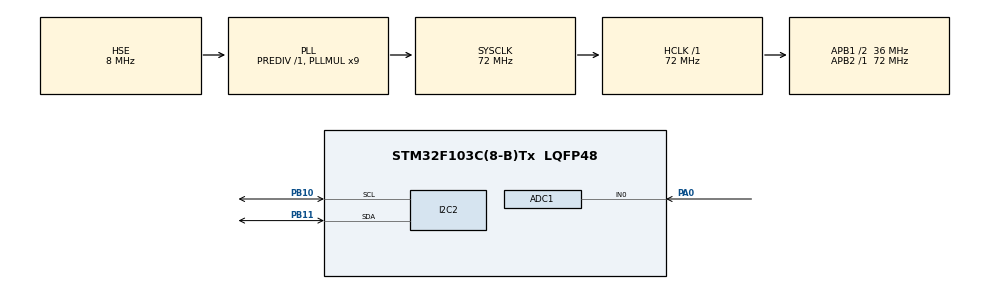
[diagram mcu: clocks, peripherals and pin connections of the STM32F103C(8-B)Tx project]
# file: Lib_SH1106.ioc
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Mcu.Family=STM32F1
RCC.PLLSourceVirtual=RCC_PLLSOURCE_HSE
PC15-OSC32_OUT.Mode=LSE-External-Oscillator
PD1-OSC_OUT.Mode=HSE-External-Oscillator
PB10.Mode=I2C
ADC1.ContinuousConvMode=ENABLE
PD0-OSC_IN.Signal=RCC_OSC_IN
RCC.APB1CLKDivider=RCC_HCLK_DIV2
PC14-OSC32_IN.Signal=RCC_OSC32_IN
PB11.Signal=I2C2_SDA
RCC.SYSCLKSource=RCC_SYSCLKSOURCE_PLLCLK
ProjectManager.StackSize=0x400
PA0-WKUP.Signal=ADCx_IN0
PD1-OSC_OUT.Signal=RCC_OSC_OUT
RCC.ADCPresc=RCC_ADCPCLK2_DIV6
PA13.Signal=SYS_JTMS-SWDIO
PB11.Mode=I2C
ProjectManager.TargetToolchain=STM32CubeIDE
RCC.HCLKFreq_Value=72000000
RCC.APB2TimFreq_Value=72000000
ADC1.Channel-1\#ChannelRegularConversion=ADC_CHANNEL_0
RCC.USBFreq_Value=72000000
PC15-OSC32_OUT.Signal=RCC_OSC32_OUT
RCC.AHBFreq_Value=72000000
PD0-OSC_IN.Mode=HSE-External-Oscillator
PB10.Signal=I2C2_SCL
board=custom
RCC.PLLMUL=RCC_PLL_MUL9
RCC.APB2Freq_Value=72000000
PC14-OSC32_IN.Mode=LSE-External-Oscillator
PA14.Mode=Serial_Wire
SH.ADCx_IN0.0=ADC1_IN0,IN0
ADC1.NbrOfConversion=1
PA13.Mode=Serial_Wire
Mcu.Name=STM32F103C(8-B)Tx
ADC1.SamplingTime-1\#ChannelRegularConversion=ADC_SAMPLETIME_1CYCLE_5
RCC.SYSCLKFreq_VALUE=72000000
Mcu.Package=LQFP48
ADC1.master=1
ADC1.Rank-1\#ChannelRegularConversion=1
PA14.Signal=SYS_JTCK-SWCLK
ProjectManager.HeapSize=0x200
NVIC.PriorityGroup=NVIC_PRIORITYGROUP_4
ADC1.NbrOfConversionFlag=1
RCC.APB1TimFreq_Value=72000000
RCC.APB1Freq_Value=36000000
I2C2.I2C_Mode=I2C_Fast

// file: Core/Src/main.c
/* USER CODE BEGIN Header */
/**
  ******************************************************************************
  * @file           : main.c
  * @brief          : Main program body
  ******************************************************************************
  * @attention
  *
  * <h2><center>&copy; Copyright (c) 2021 STMicroelectronics.
  * All rights reserved.</center></h2>
  *
  * This software component is licensed by ST under BSD 3-Clause license,
  * the "License"; You may not use this file except in compliance with the
  * License. You may obtain a copy of the License at:
  *                        opensource.org/licenses/BSD-3-Clause
  *
  ******************************************************************************
  */
/* USER CODE END Header */
#include "main.h"
#include "adc.h"
#include "i2c.h"
#include "gpio.h"

/* USER CODE BEGIN Includes */
#include <stdlib.h>
#include <usr/J3_SH1106.h>
#include <usr/font.h>

/* USER CODE END Includes */

/* USER CODE BEGIN PV */
//------------------------------------------------------------------------------
// File generated by LCD Assistant
// http://en.radzio.dxp.pl/bitmap_converter/
//------------------------------------------------------------------------------

const uint8_t pong [] = {
	0x00, 0x00, 0x00, 0x00, 0x00, 0x00, 0x00, 0x00, 0x00, 0x00, 0x00, 0x00, 0x00, 0x00, 0x00, 0x00,
	0x3F, 0xFF, 0xF0, 0x00, 0x1F, 0xFF, 0x80, 0x07, 0xFC, 0x07, 0xFE, 0x00, 0x1F, 0xFF, 0xF8, 0x00,
	0x7F, 0xFF, 0xF0, 0x00, 0x1F, 0xFF, 0x80, 0x0F, 0xFC, 0x07, 0xFF, 0x00, 0x3F, 0xFF, 0xF8, 0x00,
	0x40, 0x00, 0x10, 0x00, 0x10, 0x00, 0x00, 0x08, 0x00, 0x04, 0x01, 0x00, 0x20, 0x00, 0x08, 0x00,
	0x4F, 0xFF, 0xD0, 0x00, 0x17, 0xFE, 0x00, 0x09, 0xF0, 0x04, 0xF9, 0x00, 0x2F, 0xFF, 0xE8, 0x00,
	0x4F, 0xFF, 0xD0, 0x00, 0x17, 0xFE, 0x00, 0x09, 0xF0, 0x04, 0xF9, 0x00, 0x2F, 0xFF, 0xE8, 0x00,
	0x4F, 0xC0, 0xCF, 0x01, 0xF6, 0x06, 0x7C, 0x09, 0xF3, 0xE4, 0xF9, 0x03, 0xEC, 0x00, 0x08, 0x00,
	0x4F, 0xDE, 0xC1, 0x01, 0x06, 0xF6, 0x04, 0x09, 0xF0, 0x24, 0xF9, 0x02, 0x0C, 0xFF, 0xF8, 0x00,
	0x4F, 0xDE, 0xFD, 0x01, 0x7E, 0xF3, 0xE4, 0x09, 0xFF, 0xA4, 0xF9, 0x02, 0xFC, 0x80, 0x00, 0x00,
	0x4F, 0xDE, 0xFD, 0x01, 0x7E, 0xF3, 0xE4, 0x09, 0xFF, 0xA4, 0xF9, 0x02, 0xFC, 0x80, 0x00, 0x00,
	0x4F, 0xDE, 0xE1, 0x01, 0x7E, 0xF3, 0xE4, 0x09, 0xFF, 0xBC, 0xF9, 0x02, 0xFC, 0x9F, 0xF8, 0x00,
	0x4F, 0xC0, 0xDF, 0x01, 0x7E, 0xF3, 0xE4, 0x09, 0xFF, 0x81, 0xF9, 0x02, 0xFC, 0xB0, 0x08, 0x00,
	0x4F, 0xF3, 0xD0, 0x01, 0x7E, 0xF3, 0xE4, 0x09, 0xFF, 0xE7, 0xF9, 0x02, 0xFC, 0xB0, 0x08, 0x00,
	0x4F, 0xFF, 0xD0, 0x01, 0x7E, 0xF3, 0xE4, 0x09, 0xFF, 0xFF, 0xF9, 0x02, 0xFC, 0xB7, 0xE8, 0x00,
	0x4F, 0xFF, 0xD0, 0x01, 0x7E, 0xF3, 0xE4, 0x09, 0xFF, 0xFF, 0xF9, 0x02, 0xFC, 0xB7, 0xE8, 0x00,
	0x4F, 0xDF, 0xF0, 0x01, 0x7E, 0xF3, 0xE4, 0x09, 0xF3, 0xDF, 0xF9, 0x02, 0xFC, 0xB7, 0xE8, 0x00,
	0x4F, 0xD0, 0x00, 0x01, 0x7E, 0xF3, 0xE4, 0x09, 0xF0, 0x5F, 0xF9, 0x02, 0xFC, 0xB7, 0xE8, 0x00,
	0x4F, 0xD0, 0x00, 0x01, 0x7E, 0xF3, 0xE4, 0x09, 0xF0, 0x5F, 0xF9, 0x02, 0xFC, 0xB7, 0xE8, 0x00,
	0x4F, 0xD0, 0x00, 0x01, 0x7E, 0xF3, 0xE4, 0x09, 0xF0, 0x5F, 0xF9, 0x02, 0xFC, 0xB7, 0xE8, 0x00,
	0x4F, 0xD0, 0x00, 0x01, 0x06, 0xF6, 0x04, 0x09, 0xF0, 0x41, 0xF9, 0x02, 0x0C, 0xF6, 0x18, 0x00,
	0x4F, 0xD0, 0x00, 0x00, 0xF7, 0x0E, 0x78, 0x09, 0xF0, 0x3C, 0xF9, 0x01, 0xE7, 0x0E, 0xF0, 0x00,
	0x4F, 0xD0, 0x00, 0x00, 0x17, 0xFE, 0x00, 0x09, 0xF0, 0x04, 0xF9, 0x00, 0x6F, 0xFE, 0x80, 0x00,
	0x4F, 0xD0, 0x00, 0x00, 0x17, 0xFE, 0x00, 0x09, 0xF0, 0x04, 0xF9, 0x00, 0x2F, 0xFE, 0x80, 0x00,
	0x40, 0x10, 0x00, 0x00, 0x10, 0x00, 0x00, 0x08, 0x00, 0x04, 0x01, 0x00, 0x20, 0x00, 0x80, 0x00,
	0x3F, 0xE0, 0x00, 0x00, 0x1F, 0xFF, 0x80, 0x07, 0xFC, 0x07, 0xFE, 0x00, 0x1F, 0xFF, 0x80, 0x00,
	0x00, 0x00, 0x00, 0x00, 0x00, 0x00, 0x00, 0x00, 0x00, 0x00, 0x00, 0x00, 0x00, 0x00, 0x00, 0x00,
	0x00, 0x00, 0x00, 0x00, 0x00, 0x00, 0x00, 0x00, 0x00, 0x00, 0x00, 0x00, 0x00, 0x00, 0x00, 0x00,
	0x00, 0x00, 0x00, 0x00, 0x00, 0x00, 0x00, 0x00, 0x00, 0x00, 0x00, 0x00, 0x00, 0x00, 0x00, 0x00,
	0x00, 0x00, 0x00, 0x00, 0x00, 0x00, 0x00, 0x00, 0x00, 0x00, 0x00, 0x00, 0x00, 0x00, 0x00, 0x00,
	0x00, 0x00, 0x00, 0x00, 0x00, 0x00, 0x00, 0x00, 0x00, 0x00, 0x00, 0x00, 0x00, 0x00, 0x00, 0x00,
	0x00, 0x00, 0x00, 0x00, 0x00, 0x00, 0x00, 0x00, 0x00, 0x00, 0x00, 0x00, 0x00, 0x00, 0x00, 0x00,
	0x00, 0x00, 0x00, 0x00, 0x00, 0x00, 0x00, 0x00, 0x00, 0x00, 0x00, 0x00, 0x00, 0x00, 0x00, 0x00
	};

/* USER CODE END PV */

void SystemClock_Config(void);

/* USER CODE BEGIN 0 */

typedef struct {
  uint8_t tamX;
  uint8_t tamY;
  uint8_t posX;
  uint8_t posY;
  uint8_t pontos;
} TJogador;

typedef struct {
  float velX;
  float velY;
  uint8_t posX;
  uint8_t posY;
} TBola;

void desenhaBola(TOLED* _oled, TBola* _bola);
void desenhaJogador(TOLED* _oled, TJogador* _jogador);

uint16_t getValorPot1();

TJogador* Jogador_new(){
  TJogador* auxJogador;

  auxJogador = malloc(sizeof(TJogador));

  return auxJogador;
}

TBola* Bola_new(){
  TBola* auxBola;

  auxBola = malloc(sizeof(TBola));

  return auxBola;
}

/* USER CODE END 0 */

int main(void)
{

  /* MCU Configuration--------------------------------------------------------*/

  /* Reset of all peripherals, Initializes the Flash interface and the Systick. */
  HAL_Init();

  /* Configure the system clock */
  SystemClock_Config();

  /* Initialize all configured peripherals */
  MX_GPIO_Init();
  MX_I2C2_Init();
  MX_ADC1_Init();

  /* Infinite loop */
  /* USER CODE BEGIN WHILE */
  TOLED* oled;
  TOLED* oledBuffer;

  oled = J3_SH1106_new(&hi2c2,0x78);
  oledBuffer = J3_SH1106_new(NULL,0x00);

  HAL_Delay(1000); // Espera estabilizar o display

  J3_SH1106_offDisplay(oled);
  J3_SH1106_setNormal(oled);
  J3_SH1106_setContrast(oled,255);
  //J3_SH1106_onDisplay(oled);
  J3_SH1106_setDisplayClock(oled);
  J3_SH1106_clrDisplay(oled);

  TJogador *J1, *J2;
  TBola* bola;

  bola = Bola_new();
  bola->posX = 63;
  bola->posY = 3;
  bola->velX = 2;
  bola->velY = 3;

  J1 = Jogador_new();
  J1->tamX = 5;
  J1->tamY = 15;
  J1->posX = 5;
  J1->posY = 30;
  J1->pontos = 0;

  J2 = Jogador_new();
  J2->tamX = 5;
  J2->tamY = 15;
  J2->posX = 122;
  J2->posY = 30;
  J2->pontos = 0;

  int16_t adP1;

  J3_SH1106_draw(oled, (uint8_t *)pong, 0,0,128,32);
  HAL_Delay(7000);
  J3_SH1106_clrDisplayByBuffer(oled);

  HAL_ADCEx_Calibration_Start(&hadc1);
  while (1)
  {
    /* USER CODE END WHILE */

    /* USER CODE BEGIN 3 */

	//J3_SH1106_clrDisplay(oled);
	J3_SH1106_clrBuffer(oledBuffer);

	J3_SH1106_setBox(oledBuffer, 0,0,127,63,0);
	J3_SH1106_lineDash(oledBuffer, 63,0,63,127);
	J3_SH1106_lineDash(oledBuffer, 64,0,64,127);

	desenhaBola(oledBuffer, bola);
	desenhaJogador(oledBuffer, J1);
	desenhaJogador(oledBuffer, J2);

	J3_SH1106_fillBuffer2(oled, oledBuffer);
	HAL_Delay(20);

	//bola->posX = bola->posX + bola->velX;
	bola->posX += bola->velX;
	bola->posY += bola->velY;

	if(bola->posX >= 120){
	  if(bola->posY >= (J2->posY-5) && bola->posY <= (J2->posY+5)){
	    bola->velX = bola->velX * (-1);
	    bola->velY = bola->velY * (-1);
	  }
      if(bola->posX >= 123){
    	  bola->posX = 64;
		  bola->velX = bola->velX * (-1);
		  bola->velX = 1;
	  }
	}

	if(bola->posX <= 7){
	  if(bola->posY >= (J1->posY-5) && bola->posY <= (J1->posY+5)){
	    bola->velX = bola->velX * (-1);
	    bola->velY = bola->velY * (-1);
	  }
      if (bola->posX <= 4){
    	  bola->posX = 63;
		   bola->velX = bola->velX * (-1);
		   bola->velX = 1;
	  }
	}

	if(bola->posY >= 61){
	  bola->posY = 61;
	  bola->velY = bola->velY * (-1);
	}
	if(bola->posY <= 2){
	  bola->posY = 2;
	  bola->velY = bola->velY * (-1);
	}

/*
	if(bola->posX >= 72){
		if(J2->posY > bola->posY){
		  J2->posY = J2->posY - 2;
		  if(J2->posY <= 6)
		    J2->posY = 6;
		}
		if(J2->posY < bola->posY){
    	  J2->posY = J2->posY + 2;
		  if(J2->posY > 58 )
		    J2->posY = 58;
		}
	 }
*/
	 if(bola->posX <= 55){
		if(J1->posY > bola->posY){
		  J1->posY = J1->posY - 2;
		  if(J1->posY <= 6)
		    J1->posY = 6;
		}
		if(J1->posY < bola->posY){
    	  J1->posY = J1->posY + 2;
		  if(J1->posY > 58 )
		    J1->posY = 58;
		}
	 }

	 /* 12bits ADC = 4096 */
	 /* 54                */

	 HAL_ADC_Start(&hadc1);

	 HAL_ADC_PollForConversion(&hadc1, 200);
	 adP1 = HAL_ADC_GetValue(&hadc1);
	 HAL_ADC_Stop(&hadc1);

	 J2->posY = (adP1 / 81) ;

  }
  /* USER CODE END 3 */
}

void SystemClock_Config(void)
{
  RCC_OscInitTypeDef RCC_OscInitStruct = {0};
  RCC_ClkInitTypeDef RCC_ClkInitStruct = {0};
  RCC_PeriphCLKInitTypeDef PeriphClkInit = {0};

  /** Initializes the RCC Oscillators according to the specified parameters
  * in the RCC_OscInitTypeDef structure.
  */
  RCC_OscInitStruct.OscillatorType = RCC_OSCILLATORTYPE_HSE;
  RCC_OscInitStruct.HSEState = RCC_HSE_ON;
  RCC_OscInitStruct.HSEPredivValue = RCC_HSE_PREDIV_DIV1;
  RCC_OscInitStruct.HSIState = RCC_HSI_ON;
  RCC_OscInitStruct.PLL.PLLState = RCC_PLL_ON;
  RCC_OscInitStruct.PLL.PLLSource = RCC_PLLSOURCE_HSE;
  RCC_OscInitStruct.PLL.PLLMUL = RCC_PLL_MUL9;
  if (HAL_RCC_OscConfig(&RCC_OscInitStruct) != HAL_OK)
  {
    Error_Handler();
  }
  /** Initializes the CPU, AHB and APB buses clocks
  */
  RCC_ClkInitStruct.ClockType = RCC_CLOCKTYPE_HCLK|RCC_CLOCKTYPE_SYSCLK
                              |RCC_CLOCKTYPE_PCLK1|RCC_CLOCKTYPE_PCLK2;
  RCC_ClkInitStruct.SYSCLKSource = RCC_SYSCLKSOURCE_PLLCLK;
  RCC_ClkInitStruct.AHBCLKDivider = RCC_SYSCLK_DIV1;
  RCC_ClkInitStruct.APB1CLKDivider = RCC_HCLK_DIV2;
  RCC_ClkInitStruct.APB2CLKDivider = RCC_HCLK_DIV1;

  if (HAL_RCC_ClockConfig(&RCC_ClkInitStruct, FLASH_LATENCY_2) != HAL_OK)
  {
    Error_Handler();
  }
  PeriphClkInit.PeriphClockSelection = RCC_PERIPHCLK_ADC;
  PeriphClkInit.AdcClockSelection = RCC_ADCPCLK2_DIV6;
  if (HAL_RCCEx_PeriphCLKConfig(&PeriphClkInit) != HAL_OK)
  {
    Error_Handler();
  }
}

/* USER CODE BEGIN 4 */
void desenhaBola(TOLED* _oled, TBola* _bola){
  J3_SH1106_setPixel(_oled,_bola->posX-1,_bola->posY-1);
  J3_SH1106_setPixel(_oled,_bola->posX-1,_bola->posY);
  J3_SH1106_setPixel(_oled,_bola->posX-1,_bola->posY+1);

  J3_SH1106_setPixel(_oled,_bola->posX,_bola->posY-1);
  J3_SH1106_setPixel(_oled,_bola->posX,_bola->posY);
  J3_SH1106_setPixel(_oled,_bola->posX,_bola->posY+1);

  J3_SH1106_setPixel(_oled,_bola->posX+1,_bola->posY-1);
  J3_SH1106_setPixel(_oled,_bola->posX+1,_bola->posY);
  J3_SH1106_setPixel(_oled,_bola->posX+1,_bola->posY+1);
}

void desenhaJogador(TOLED* _oled, TJogador* _jogador) {
  const int8_t play_altura = 5;
  const int8_t play_largura = 1;
  J3_SH1106_line(_oled, _jogador->posX-play_largura,_jogador->posY-play_altura,_jogador->posX+play_largura,_jogador->posY-play_altura);
  J3_SH1106_line(_oled, _jogador->posX-play_largura,_jogador->posY-play_altura,_jogador->posX-play_largura,_jogador->posY+play_altura);
  J3_SH1106_line(_oled, _jogador->posX-play_largura,_jogador->posY+play_altura,_jogador->posX+play_largura,_jogador->posY+play_altura);
  J3_SH1106_line(_oled, _jogador->posX+play_largura,_jogador->posY+play_altura,_jogador->posX+play_largura,_jogador->posY-play_altura);
}

/* USER CODE END 4 */

void Error_Handler(void)
{
  __disable_irq();
  while (1)
  {
  }
}

/************************ (C) COPYRIGHT STMicroelectronics *****END OF FILE****/
